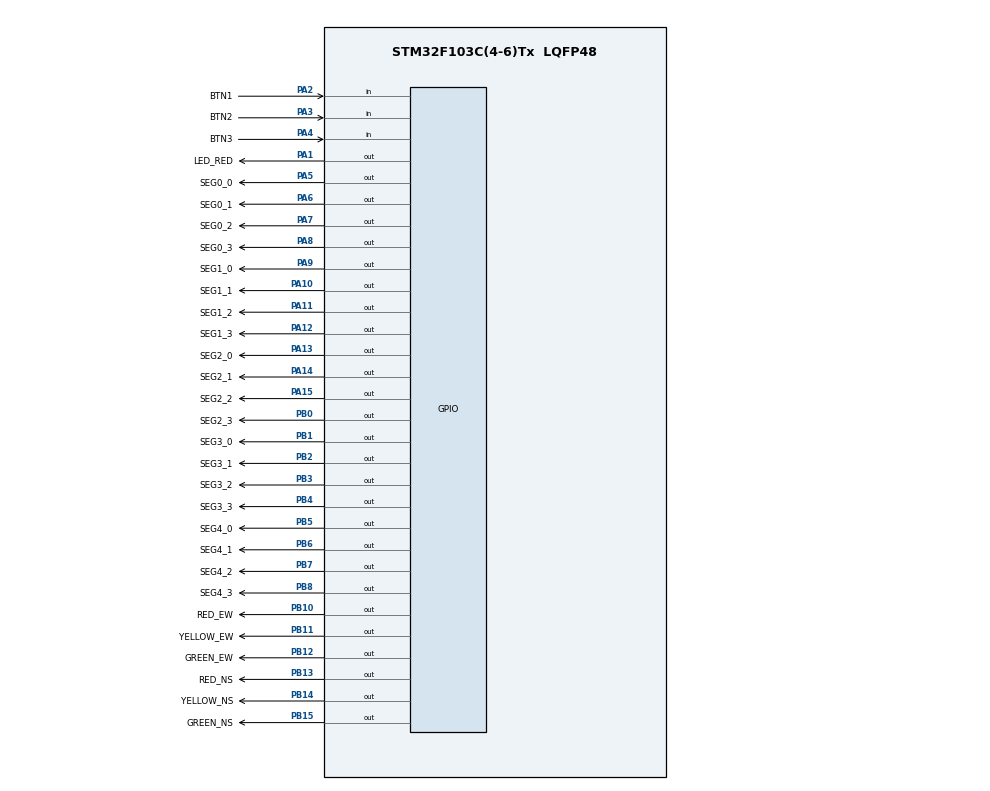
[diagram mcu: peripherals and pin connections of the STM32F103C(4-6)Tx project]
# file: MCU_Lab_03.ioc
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Mcu.Family=STM32F1
Mcu.Name=STM32F103C(4-6)Tx
Mcu.Package=LQFP48
NVIC.PriorityGroup=NVIC_PRIORITYGROUP_4
NVIC.TIM2_IRQn=true\:0\:0\:false\:false\:true\:true\:true\:true
PA1.GPIO_Label=LED_RED
PA1.PinState=GPIO_PIN_SET
PA1.Signal=GPIO_Output
PA10.GPIO_Label=SEG1_1
PA10.PinState=GPIO_PIN_RESET
PA10.Signal=GPIO_Output
PA11.GPIO_Label=SEG1_2
PA11.PinState=GPIO_PIN_RESET
PA11.Signal=GPIO_Output
PA12.GPIO_Label=SEG1_3
PA12.PinState=GPIO_PIN_RESET
PA12.Signal=GPIO_Output
PA13.GPIO_Label=SEG2_0
PA13.PinState=GPIO_PIN_RESET
PA13.Signal=GPIO_Output
PA14.GPIO_Label=SEG2_1
PA14.PinState=GPIO_PIN_RESET
PA14.Signal=GPIO_Output
PA15.GPIO_Label=SEG2_2
PA15.PinState=GPIO_PIN_RESET
PA15.Signal=GPIO_Output
PA2.GPIO_Label=BTN1
PA2.GPIO_PuPd=GPIO_PULLUP
PA2.Signal=GPIO_Input
PA3.GPIO_Label=BTN2
PA3.GPIO_PuPd=GPIO_PULLUP
PA3.Signal=GPIO_Input
PA4.GPIO_Label=BTN3
PA4.GPIO_PuPd=GPIO_PULLUP
PA4.Signal=GPIO_Input
PA5.GPIO_Label=SEG0_0
PA5.PinState=GPIO_PIN_RESET
PA5.Signal=GPIO_Output
PA6.GPIO_Label=SEG0_1
PA6.PinState=GPIO_PIN_RESET
PA6.Signal=GPIO_Output
PA7.GPIO_Label=SEG0_2
PA7.PinState=GPIO_PIN_RESET
PA7.Signal=GPIO_Output
PA8.GPIO_Label=SEG0_3
PA8.Signal=GPIO_Output
PA9.GPIO_Label=SEG1_0
PA9.PinState=GPIO_PIN_RESET
PA9.Signal=GPIO_Output
PB0.GPIO_Label=SEG2_3
PB0.Signal=GPIO_Output
PB1.GPIO_Label=SEG3_0
PB1.Signal=GPIO_Output
PB10.GPIO_Label=RED_EW
PB10.PinState=GPIO_PIN_SET
PB10.Signal=GPIO_Output
PB11.GPIO_Label=YELLOW_EW
PB11.PinState=GPIO_PIN_SET
PB11.Signal=GPIO_Output
PB12.GPIO_Label=GREEN_EW
PB12.PinState=GPIO_PIN_SET
PB12.Signal=GPIO_Output
PB13.GPIO_Label=RED_NS
PB13.PinState=GPIO_PIN_SET
PB13.Signal=GPIO_Output
PB14.GPIO_Label=YELLOW_NS
PB14.PinState=GPIO_PIN_SET
PB14.Signal=GPIO_Output
PB15.GPIO_Label=GREEN_NS
PB15.PinState=GPIO_PIN_SET
PB15.Signal=GPIO_Output
PB2.GPIO_Label=SEG3_1
PB2.Signal=GPIO_Output
PB3.GPIO_Label=SEG3_2
PB3.Signal=GPIO_Output
PB4.GPIO_Label=SEG3_3
PB4.Signal=GPIO_Output
PB5.GPIO_Label=SEG4_0
PB5.PinState=GPIO_PIN_RESET
PB5.Signal=GPIO_Output
PB6.GPIO_Label=SEG4_1
PB6.PinState=GPIO_PIN_RESET
PB6.Signal=GPIO_Output
PB7.GPIO_Label=SEG4_2
PB7.PinState=GPIO_PIN_RESET
PB7.Signal=GPIO_Output
PB8.GPIO_Label=SEG4_3
PB8.PinState=GPIO_PIN_RESET
PB8.Signal=GPIO_Output
ProjectManager.HeapSize=0x200
ProjectManager.StackSize=0x400
ProjectManager.TargetToolchain=STM32CubeIDE
RCC.APB1Freq_Value=8000000
RCC.APB2Freq_Value=8000000
TIM2.Period=9
TIM2.Prescaler=7999
VP_SYS_VS_ND.Mode=No_Debug
VP_TIM2_VS_ClockSourceINT.Mode=Internal
board=custom

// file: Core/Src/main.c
/* USER CODE BEGIN Header */
/**
  ******************************************************************************
  * @file           : main.c
  * @brief          : Main program body
  ******************************************************************************
  * @attention
  *
  * Copyright (c) 2025 STMicroelectronics.
  * All rights reserved.
  *
  * This software is licensed under terms that can be found in the LICENSE file
  * in the root directory of this software component.
  * If no LICENSE file comes with this software, it is provided AS-IS.
  *
  ******************************************************************************
  */
/* USER CODE END Header */
#include "main.h"

TIM_HandleTypeDef htim2;

void SystemClock_Config(void);
static void MX_GPIO_Init(void);
static void MX_TIM2_Init(void);

int main(void)
{

  /* MCU Configuration--------------------------------------------------------*/

  /* Reset of all peripherals, Initializes the Flash interface and the Systick. */
  HAL_Init();

  /* Configure the system clock */
  SystemClock_Config();

  /* Initialize all configured peripherals */
  MX_GPIO_Init();
  MX_TIM2_Init();
  /* USER CODE BEGIN 2 */
  HAL_Delay(100);
  HAL_TIM_Base_Start_IT(&htim2);

  setTimer(0, 1000);
  setTimer(7, 500);
  /* USER CODE END 2 */

  /* Infinite loop */
  /* USER CODE BEGIN WHILE */
  while (1)
  {
	if (isTimerExpired(0) == 1)
	{
		setTimer(0, 1000);
		led_red_blink();
	}
	//you only need to add the fsm function here
	fsm_for_input_processing();
	run_background();
    /* USER CODE END WHILE */

  }
}

void SystemClock_Config(void)
{
  RCC_OscInitTypeDef RCC_OscInitStruct = {0};
  RCC_ClkInitTypeDef RCC_ClkInitStruct = {0};

  /** Initializes the RCC Oscillators according to the specified parameters
  * in the RCC_OscInitTypeDef structure.
  */
  RCC_OscInitStruct.OscillatorType = RCC_OSCILLATORTYPE_HSI;
  RCC_OscInitStruct.HSIState = RCC_HSI_ON;
  RCC_OscInitStruct.HSICalibrationValue = RCC_HSICALIBRATION_DEFAULT;
  RCC_OscInitStruct.PLL.PLLState = RCC_PLL_NONE;
  if (HAL_RCC_OscConfig(&RCC_OscInitStruct) != HAL_OK)
  {
    Error_Handler();
  }

  /** Initializes the CPU, AHB and APB buses clocks
  */
  RCC_ClkInitStruct.ClockType = RCC_CLOCKTYPE_HCLK|RCC_CLOCKTYPE_SYSCLK
                              |RCC_CLOCKTYPE_PCLK1|RCC_CLOCKTYPE_PCLK2;
  RCC_ClkInitStruct.SYSCLKSource = RCC_SYSCLKSOURCE_HSI;
  RCC_ClkInitStruct.AHBCLKDivider = RCC_SYSCLK_DIV1;
  RCC_ClkInitStruct.APB1CLKDivider = RCC_HCLK_DIV1;
  RCC_ClkInitStruct.APB2CLKDivider = RCC_HCLK_DIV1;

  if (HAL_RCC_ClockConfig(&RCC_ClkInitStruct, FLASH_LATENCY_0) != HAL_OK)
  {
    Error_Handler();
  }
}

static void MX_TIM2_Init(void)
{

  TIM_ClockConfigTypeDef sClockSourceConfig = {0};
  TIM_MasterConfigTypeDef sMasterConfig = {0};

  htim2.Instance = TIM2;
  htim2.Init.Prescaler = 7999;
  htim2.Init.CounterMode = TIM_COUNTERMODE_UP;
  htim2.Init.Period = 9;
  htim2.Init.ClockDivision = TIM_CLOCKDIVISION_DIV1;
  htim2.Init.AutoReloadPreload = TIM_AUTORELOAD_PRELOAD_DISABLE;
  if (HAL_TIM_Base_Init(&htim2) != HAL_OK)
  {
    Error_Handler();
  }
  sClockSourceConfig.ClockSource = TIM_CLOCKSOURCE_INTERNAL;
  if (HAL_TIM_ConfigClockSource(&htim2, &sClockSourceConfig) != HAL_OK)
  {
    Error_Handler();
  }
  sMasterConfig.MasterOutputTrigger = TIM_TRGO_RESET;
  sMasterConfig.MasterSlaveMode = TIM_MASTERSLAVEMODE_DISABLE;
  if (HAL_TIMEx_MasterConfigSynchronization(&htim2, &sMasterConfig) != HAL_OK)
  {
    Error_Handler();
  }

}

static void MX_GPIO_Init(void)
{
  GPIO_InitTypeDef GPIO_InitStruct = {0};

  /* GPIO Ports Clock Enable */
  __HAL_RCC_GPIOA_CLK_ENABLE();
  __HAL_RCC_GPIOB_CLK_ENABLE();

  /*Configure GPIO pin Output Level */
  HAL_GPIO_WritePin(LED_RED_GPIO_Port, LED_RED_Pin, GPIO_PIN_SET);

  /*Configure GPIO pin Output Level */
  HAL_GPIO_WritePin(GPIOA, SEG0_0_Pin|SEG0_1_Pin|SEG0_2_Pin|SEG0_3_Pin
                          |SEG1_0_Pin|SEG1_1_Pin|SEG1_2_Pin|SEG1_3_Pin
                          |SEG2_0_Pin|SEG2_1_Pin|SEG2_2_Pin, GPIO_PIN_RESET);

  /*Configure GPIO pin Output Level */
  HAL_GPIO_WritePin(GPIOB, SEG2_3_Pin|SEG3_0_Pin|SEG3_1_Pin|SEG3_2_Pin
                          |SEG3_3_Pin|SEG4_0_Pin|SEG4_1_Pin|SEG4_2_Pin
                          |SEG4_3_Pin, GPIO_PIN_RESET);

  /*Configure GPIO pin Output Level */
  HAL_GPIO_WritePin(GPIOB, RED_EW_Pin|YELLOW_EW_Pin|GREEN_EW_Pin|RED_NS_Pin
                          |YELLOW_NS_Pin|GREEN_NS_Pin, GPIO_PIN_SET);

  /*Configure GPIO pins : LED_RED_Pin SEG0_0_Pin SEG0_1_Pin SEG0_2_Pin
                           SEG0_3_Pin SEG1_0_Pin SEG1_1_Pin SEG1_2_Pin
                           SEG1_3_Pin SEG2_0_Pin SEG2_1_Pin SEG2_2_Pin */
  GPIO_InitStruct.Pin = LED_RED_Pin|SEG0_0_Pin|SEG0_1_Pin|SEG0_2_Pin
                          |SEG0_3_Pin|SEG1_0_Pin|SEG1_1_Pin|SEG1_2_Pin
                          |SEG1_3_Pin|SEG2_0_Pin|SEG2_1_Pin|SEG2_2_Pin;
  GPIO_InitStruct.Mode = GPIO_MODE_OUTPUT_PP;
  GPIO_InitStruct.Pull = GPIO_NOPULL;
  GPIO_InitStruct.Speed = GPIO_SPEED_FREQ_LOW;
  HAL_GPIO_Init(GPIOA, &GPIO_InitStruct);

  /*Configure GPIO pins : BTN1_Pin BTN2_Pin BTN3_Pin */
  GPIO_InitStruct.Pin = BTN1_Pin|BTN2_Pin|BTN3_Pin;
  GPIO_InitStruct.Mode = GPIO_MODE_INPUT;
  GPIO_InitStruct.Pull = GPIO_PULLUP;
  HAL_GPIO_Init(GPIOA, &GPIO_InitStruct);

  /*Configure GPIO pins : SEG2_3_Pin SEG3_0_Pin SEG3_1_Pin RED_EW_Pin
                           YELLOW_EW_Pin GREEN_EW_Pin RED_NS_Pin YELLOW_NS_Pin
                           GREEN_NS_Pin SEG3_2_Pin SEG3_3_Pin SEG4_0_Pin
                           SEG4_1_Pin SEG4_2_Pin SEG4_3_Pin */
  GPIO_InitStruct.Pin = SEG2_3_Pin|SEG3_0_Pin|SEG3_1_Pin|RED_EW_Pin
                          |YELLOW_EW_Pin|GREEN_EW_Pin|RED_NS_Pin|YELLOW_NS_Pin
                          |GREEN_NS_Pin|SEG3_2_Pin|SEG3_3_Pin|SEG4_0_Pin
                          |SEG4_1_Pin|SEG4_2_Pin|SEG4_3_Pin;
  GPIO_InitStruct.Mode = GPIO_MODE_OUTPUT_PP;
  GPIO_InitStruct.Pull = GPIO_NOPULL;
  GPIO_InitStruct.Speed = GPIO_SPEED_FREQ_LOW;
  HAL_GPIO_Init(GPIOB, &GPIO_InitStruct);

}

void Error_Handler(void)
{
  __disable_irq();
  while (1)
  {
  }
}
